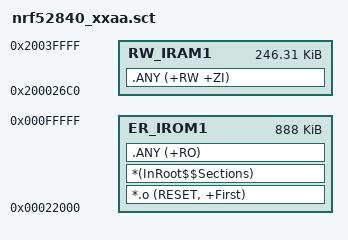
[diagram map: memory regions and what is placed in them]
; *************************************************************
; *** Scatter-Loading Description File generated by uVision ***
; *************************************************************

LR_IROM1 0x00022000 0x000DE000  {    ; load region size_region
  ER_IROM1 0x00022000 0x000DE000  {  ; load address = execution address
   *.o (RESET, +First)
   *(InRoot$$Sections)
   .ANY (+RO)
  }
  RW_IRAM1 0x200026C0 0x0003D940  {  ; RW data
   .ANY (+RW +ZI)
  }
}

